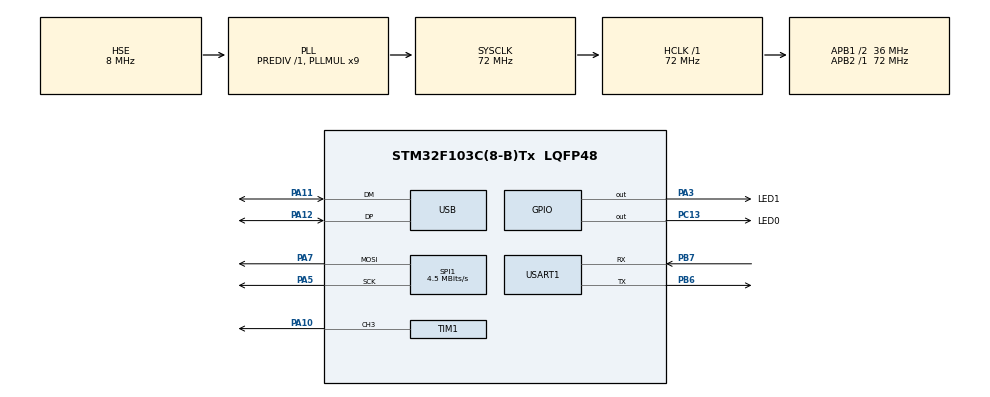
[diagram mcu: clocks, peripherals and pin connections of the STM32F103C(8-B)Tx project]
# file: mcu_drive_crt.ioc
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Dma.Request0=SPI1_TX
Dma.SPI1_TX.0.Direction=DMA_MEMORY_TO_PERIPH
Dma.SPI1_TX.0.Instance=DMA1_Channel3
Dma.SPI1_TX.0.MemDataAlignment=DMA_MDATAALIGN_BYTE
Dma.SPI1_TX.0.MemInc=DMA_MINC_ENABLE
Dma.SPI1_TX.0.Mode=DMA_NORMAL
Dma.SPI1_TX.0.PeriphDataAlignment=DMA_PDATAALIGN_BYTE
Dma.SPI1_TX.0.PeriphInc=DMA_PINC_DISABLE
Dma.SPI1_TX.0.Priority=DMA_PRIORITY_LOW
FREERTOS.Tasks01=defaultTask,0,128,StartDefaultTask,Default,NULL,Dynamic,NULL,NULL;checkTASK,-2,128,LedTask,Default,NULL,Dynamic,NULL,NULL;USB_RecTask,-3,128,USB_Recive,Default,NULL,Dynamic,NULL,NULL;Show_Task,0,128,Screen_Show,Default,NULL,Dynamic,NULL,NULL
Mcu.Family=STM32F1
Mcu.Name=STM32F103C(8-B)Tx
Mcu.Package=LQFP48
NVIC.DMA1_Channel3_IRQn=true\:5\:0\:false\:false\:true\:true\:false\:true\:true
NVIC.PriorityGroup=NVIC_PRIORITYGROUP_4
NVIC.TIM1_CC_IRQn=true\:5\:0\:false\:false\:true\:true\:true\:true\:true
NVIC.TIM2_IRQn=true\:15\:0\:false\:false\:true\:false\:false\:true\:true
NVIC.TimeBase=TIM2_IRQn
NVIC.TimeBaseIP=TIM2
NVIC.USB_LP_CAN1_RX0_IRQn=true\:5\:0\:false\:false\:true\:true\:false\:true\:true
PA10.Signal=S_TIM1_CH3
PA11.Mode=Device
PA11.Signal=USB_DM
PA12.Mode=Device
PA12.Signal=USB_DP
PA13.Mode=Serial_Wire
PA13.Signal=SYS_JTMS-SWDIO
PA14.Mode=Serial_Wire
PA14.Signal=SYS_JTCK-SWCLK
PA3.GPIO_Label=LED1
PA3.Signal=GPIO_Output
PA5.Mode=TX_Only_Simplex_Unidirect_Master
PA5.Signal=SPI1_SCK
PA7.Mode=TX_Only_Simplex_Unidirect_Master
PA7.Signal=SPI1_MOSI
PB6.Mode=Asynchronous
PB6.Signal=USART1_TX
PB7.Mode=Asynchronous
PB7.Signal=USART1_RX
PC13-TAMPER-RTC.GPIO_Label=LED0
PC13-TAMPER-RTC.Signal=GPIO_Output
PD0-OSC_IN.Mode=HSE-External-Oscillator
PD0-OSC_IN.Signal=RCC_OSC_IN
PD1-OSC_OUT.Mode=HSE-External-Oscillator
PD1-OSC_OUT.Signal=RCC_OSC_OUT
ProjectManager.HeapSize=0x400
ProjectManager.StackSize=0x800
ProjectManager.TargetToolchain=MDK-ARM V5.27
RCC.AHBFreq_Value=72000000
RCC.APB1CLKDivider=RCC_HCLK_DIV2
RCC.APB1Freq_Value=36000000
RCC.APB1TimFreq_Value=72000000
RCC.APB2Freq_Value=72000000
RCC.APB2TimFreq_Value=72000000
RCC.HCLKFreq_Value=72000000
RCC.PLLMUL=RCC_PLL_MUL9
RCC.PLLSourceVirtual=RCC_PLLSOURCE_HSE
RCC.SYSCLKFreq_VALUE=72000000
RCC.SYSCLKSource=RCC_SYSCLKSOURCE_PLLCLK
RCC.USBFreq_Value=48000000
RCC.USBPrescaler=RCC_USBCLKSOURCE_PLL_DIV1_5
SH.S_TIM1_CH3.0=TIM1_CH3,PWM Generation3 CH3
SPI1.BaudRatePrescaler=SPI_BAUDRATEPRESCALER_16
SPI1.CalculateBaudRate=4.5 MBits/s
SPI1.Direction=SPI_DIRECTION_2LINES
SPI1.Mode=SPI_MODE_MASTER
SPI1.VirtualType=VM_MASTER
TIM1.AutoReloadPreload=TIM_AUTORELOAD_PRELOAD_ENABLE
TIM1.Channel-Output\ Compare1\ No\ Output=TIM_CHANNEL_1
TIM1.Channel-PWM\ Generation3\ CH3=TIM_CHANNEL_3
TIM1.ClockDivision=TIM_CLOCKDIVISION_DIV1
TIM1.OC1Preload=ENABLE
TIM1.OC3Preload_PWM=ENABLE
TIM1.OCPolarity_3=TIM_OCPOLARITY_LOW
TIM1.Period=1524
TIM1.Prescaler=2
USART1.VirtualMode=VM_ASYNC
USB_DEVICE.CLASS_NAME_FS=CDC
USB_DEVICE.VirtualMode=Cdc
USB_DEVICE.VirtualModeFS=Cdc_FS
VP_FREERTOS_VS_CMSIS_V1.Mode=CMSIS_V1
VP_SYS_VS_tim2.Mode=TIM2
VP_TIM1_VS_no_output1.Mode=Output Compare1 No Output
VP_USB_DEVICE_VS_USB_DEVICE_CDC_FS.Mode=CDC_FS
board=custom

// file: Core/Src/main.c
/* USER CODE BEGIN Header */
/**
  ******************************************************************************
  * @file           : main.c
  * @brief          : Main program body
  ******************************************************************************
  * @attention
  *
  * Copyright (c) 2023 STMicroelectronics.
  * All rights reserved.
  *
  * This software is licensed under terms that can be found in the LICENSE file
  * in the root directory of this software component.
  * If no LICENSE file comes with this software, it is provided AS-IS.
  *
  ******************************************************************************
  */
/* USER CODE END Header */
#include "main.h"
#include "cmsis_os.h"
#include "dma.h"
#include "spi.h"
#include "tim.h"
#include "usart.h"
#include "usb_device.h"
#include "gpio.h"

/* USER CODE BEGIN Includes */
#include "../../USB_DEVICE/App/usbd_cdc_if.h"
/* USER CODE END Includes */

void SystemClock_Config(void);
void MX_FREERTOS_Init(void);

int main(void)
{

  /* MCU Configuration--------------------------------------------------------*/

  /* Reset of all peripherals, Initializes the Flash interface and the Systick. */
  HAL_Init();

  /* Configure the system clock */
  SystemClock_Config();

  /* Initialize all configured peripherals */
  MX_GPIO_Init();
  MX_DMA_Init();
  MX_USART1_UART_Init();
  MX_TIM1_Init();
  MX_SPI1_Init();

  /* Call init function for freertos objects (in freertos.c) */
  MX_FREERTOS_Init();

  /* Start scheduler */
  osKernelStart();

  /* We should never get here as control is now taken by the scheduler */
  /* Infinite loop */
  while (1)
  {

  }
}

void SystemClock_Config(void)
{
  RCC_OscInitTypeDef RCC_OscInitStruct = {0};
  RCC_ClkInitTypeDef RCC_ClkInitStruct = {0};
  RCC_PeriphCLKInitTypeDef PeriphClkInit = {0};

  /** Initializes the RCC Oscillators according to the specified parameters
  * in the RCC_OscInitTypeDef structure.
  */
  RCC_OscInitStruct.OscillatorType = RCC_OSCILLATORTYPE_HSE;
  RCC_OscInitStruct.HSEState = RCC_HSE_ON;
  RCC_OscInitStruct.HSEPredivValue = RCC_HSE_PREDIV_DIV1;
  RCC_OscInitStruct.HSIState = RCC_HSI_ON;
  RCC_OscInitStruct.PLL.PLLState = RCC_PLL_ON;
  RCC_OscInitStruct.PLL.PLLSource = RCC_PLLSOURCE_HSE;
  RCC_OscInitStruct.PLL.PLLMUL = RCC_PLL_MUL9;
  if (HAL_RCC_OscConfig(&RCC_OscInitStruct) != HAL_OK)
  {
    Error_Handler();
  }

  /** Initializes the CPU, AHB and APB buses clocks
  */
  RCC_ClkInitStruct.ClockType = RCC_CLOCKTYPE_HCLK|RCC_CLOCKTYPE_SYSCLK
                              |RCC_CLOCKTYPE_PCLK1|RCC_CLOCKTYPE_PCLK2;
  RCC_ClkInitStruct.SYSCLKSource = RCC_SYSCLKSOURCE_PLLCLK;
  RCC_ClkInitStruct.AHBCLKDivider = RCC_SYSCLK_DIV1;
  RCC_ClkInitStruct.APB1CLKDivider = RCC_HCLK_DIV2;
  RCC_ClkInitStruct.APB2CLKDivider = RCC_HCLK_DIV1;

  if (HAL_RCC_ClockConfig(&RCC_ClkInitStruct, FLASH_LATENCY_2) != HAL_OK)
  {
    Error_Handler();
  }
  PeriphClkInit.PeriphClockSelection = RCC_PERIPHCLK_USB;
  PeriphClkInit.UsbClockSelection = RCC_USBCLKSOURCE_PLL_DIV1_5;
  if (HAL_RCCEx_PeriphCLKConfig(&PeriphClkInit) != HAL_OK)
  {
    Error_Handler();
  }
}

void HAL_TIM_PeriodElapsedCallback(TIM_HandleTypeDef *htim)
{
  if (htim->Instance == TIM2) {
    HAL_IncTick();
  }
}

void Error_Handler(void)
{
  __disable_irq();
  while (1)
  {
  }
}

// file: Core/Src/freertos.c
/* USER CODE BEGIN Header */
/**
  ******************************************************************************
  * File Name          : freertos.c
  * Description        : Code for freertos applications
  ******************************************************************************
  * @attention
  *
  * Copyright (c) 2023 STMicroelectronics.
  * All rights reserved.
  *
  * This software is licensed under terms that can be found in the LICENSE file
  * in the root directory of this software component.
  * If no LICENSE file comes with this software, it is provided AS-IS.
  *
  ******************************************************************************
  */
/* USER CODE END Header */

#include "FreeRTOS.h"
#include "task.h"
#include "main.h"
#include "cmsis_os.h"

/* USER CODE BEGIN Includes */
#include "screen_main.h"
#include "ntsc.h"
#include "../../USB_DEVICE/App/usbd_cdc_if.h"
/* USER CODE END Includes */

osThreadId defaultTaskHandle;
osThreadId checkTASKHandle;
osThreadId USB_RecTaskHandle;
osThreadId Show_TaskHandle;

void StartDefaultTask(void const * argument);
void LedTask(void const * argument);
void USB_Recive(void const * argument);
void Screen_Show(void const * argument);

extern void MX_USB_DEVICE_Init(void);
void MX_FREERTOS_Init(void); /* (MISRA C 2004 rule 8.1) */

/* GetIdleTaskMemory prototype (linked to static allocation support) */
void vApplicationGetIdleTaskMemory( StaticTask_t **ppxIdleTaskTCBBuffer, StackType_t **ppxIdleTaskStackBuffer, uint32_t *pulIdleTaskStackSize );

/* USER CODE BEGIN GET_IDLE_TASK_MEMORY */
static StaticTask_t xIdleTaskTCBBuffer;
static StackType_t xIdleStack[configMINIMAL_STACK_SIZE];

void vApplicationGetIdleTaskMemory( StaticTask_t **ppxIdleTaskTCBBuffer, StackType_t **ppxIdleTaskStackBuffer, uint32_t *pulIdleTaskStackSize )
{
  *ppxIdleTaskTCBBuffer = &xIdleTaskTCBBuffer;
  *ppxIdleTaskStackBuffer = &xIdleStack[0];
  *pulIdleTaskStackSize = configMINIMAL_STACK_SIZE;
  /* place for user code */
}
/* USER CODE END GET_IDLE_TASK_MEMORY */

void MX_FREERTOS_Init(void) {

  /* Create the thread(s) */
  /* definition and creation of defaultTask */
  osThreadDef(defaultTask, StartDefaultTask, osPriorityNormal, 0, 128);
  defaultTaskHandle = osThreadCreate(osThread(defaultTask), NULL);

  /* definition and creation of checkTASK */
  osThreadDef(checkTASK, LedTask, osPriorityLow, 0, 128);
  checkTASKHandle = osThreadCreate(osThread(checkTASK), NULL);

  /* definition and creation of USB_RecTask */
  osThreadDef(USB_RecTask, USB_Recive, osPriorityIdle, 0, 128);
  USB_RecTaskHandle = osThreadCreate(osThread(USB_RecTask), NULL);

  /* definition and creation of Show_Task */
  osThreadDef(Show_Task, Screen_Show, osPriorityNormal, 0, 128);
  Show_TaskHandle = osThreadCreate(osThread(Show_Task), NULL);

}

void StartDefaultTask(void const * argument)
{
  /* init code for USB_DEVICE */
  MX_USB_DEVICE_Init();
  for(;;)
  {
    osDelay(1);
  }
}

void LedTask(void const * argument)
{
  /* USER CODE BEGIN LedTask */
  /* Infinite loop */
  for(;;)
  {
	HAL_GPIO_TogglePin(LED0_GPIO_Port,LED0_Pin);
//	  USB_printf("JEELO\r\n");
    osDelay(1000);
  }
  /* USER CODE END LedTask */
}

void USB_Recive(void const * argument)
{
  /* USER CODE BEGIN USB_Recive */
  /* Infinite loop */
  for(;;)
  {
//	USB_COM();
    osDelay(20);
  }
  /* USER CODE END USB_Recive */
}

void Screen_Show(void const * argument)
{
  /* USER CODE BEGIN Screen_Show */
  Screen_TaskSetup();
  /* Infinite loop */
  for(;;)
  {
	Screen_TaskLoop();
    osDelay(5);
  }
  /* USER CODE END Screen_Show */
}
